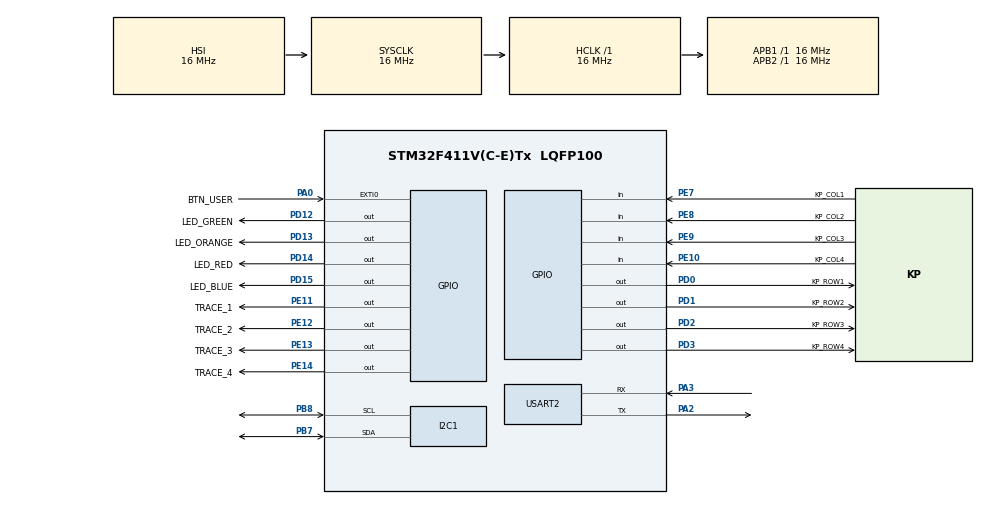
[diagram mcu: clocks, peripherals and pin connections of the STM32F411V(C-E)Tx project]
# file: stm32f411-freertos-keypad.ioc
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Dma.I2C1_TX.0.Direction=DMA_MEMORY_TO_PERIPH
Dma.I2C1_TX.0.FIFOMode=DMA_FIFOMODE_DISABLE
Dma.I2C1_TX.0.Instance=DMA1_Stream6
Dma.I2C1_TX.0.MemDataAlignment=DMA_MDATAALIGN_BYTE
Dma.I2C1_TX.0.MemInc=DMA_MINC_ENABLE
Dma.I2C1_TX.0.Mode=DMA_NORMAL
Dma.I2C1_TX.0.PeriphDataAlignment=DMA_PDATAALIGN_BYTE
Dma.I2C1_TX.0.PeriphInc=DMA_PINC_DISABLE
Dma.I2C1_TX.0.Priority=DMA_PRIORITY_LOW
Dma.Request0=I2C1_TX
FREERTOS.Tasks01=defaultTask,24,128,StartDefaultTask,Default,NULL,Dynamic,NULL,NULL
FREERTOS.configUSE_APPLICATION_TASK_TAG=1
Mcu.Family=STM32F4
Mcu.Name=STM32F411V(C-E)Tx
Mcu.Package=LQFP100
NVIC.DMA1_Stream6_IRQn=true\:5\:0\:false\:false\:true\:true\:false\:true\:true
NVIC.EXTI0_IRQn=true\:5\:0\:false\:false\:true\:true\:false\:true\:true
NVIC.I2C1_ER_IRQn=true\:5\:0\:false\:false\:true\:true\:true\:true\:true
NVIC.I2C1_EV_IRQn=true\:5\:0\:false\:false\:true\:true\:true\:true\:true
NVIC.PriorityGroup=NVIC_PRIORITYGROUP_4
NVIC.TIM1_TRG_COM_TIM11_IRQn=true\:15\:0\:false\:false\:true\:false\:false\:true\:true
NVIC.TimeBase=TIM1_TRG_COM_TIM11_IRQn
NVIC.TimeBaseIP=TIM11
PA0-WKUP.GPIO_Label=BTN_USER
PA0-WKUP.Signal=GPXTI0
PA13.Mode=Serial_Wire
PA13.Signal=SYS_JTMS-SWDIO
PA14.Mode=Serial_Wire
PA14.Signal=SYS_JTCK-SWCLK
PA2.Mode=Asynchronous
PA2.Signal=USART2_TX
PA3.Mode=Asynchronous
PA3.Signal=USART2_RX
PB7.GPIO_Pu=GPIO_PULLUP
PB7.Mode=I2C
PB7.Signal=I2C1_SDA
PB8.GPIO_Pu=GPIO_PULLUP
PB8.Mode=I2C
PB8.Signal=I2C1_SCL
PD0.GPIO_Label=KP_ROW1
PD0.GPIO_ModeDefaultOutputPP=GPIO_MODE_OUTPUT_OD
PD0.PinState=GPIO_PIN_SET
PD0.Signal=GPIO_Output
PD1.GPIO_Label=KP_ROW2
PD1.GPIO_ModeDefaultOutputPP=GPIO_MODE_OUTPUT_OD
PD1.PinState=GPIO_PIN_SET
PD1.Signal=GPIO_Output
PD12.GPIO_Label=LED_GREEN
PD12.Signal=GPIO_Output
PD13.GPIO_Label=LED_ORANGE
PD13.Signal=GPIO_Output
PD14.GPIO_Label=LED_RED
PD14.Signal=GPIO_Output
PD15.GPIO_Label=LED_BLUE
PD15.Signal=GPIO_Output
PD2.GPIO_Label=KP_ROW3
PD2.GPIO_ModeDefaultOutputPP=GPIO_MODE_OUTPUT_OD
PD2.PinState=GPIO_PIN_SET
PD2.Signal=GPIO_Output
PD3.GPIO_Label=KP_ROW4
PD3.GPIO_ModeDefaultOutputPP=GPIO_MODE_OUTPUT_OD
PD3.PinState=GPIO_PIN_SET
PD3.Signal=GPIO_Output
PE10.GPIO_Label=KP_COL4
PE10.GPIO_PuPd=GPIO_PULLUP
PE10.Signal=GPIO_Input
PE11.GPIO_Label=TRACE_1
PE11.GPIO_Speed=GPIO_SPEED_FREQ_HIGH
PE11.Signal=GPIO_Output
PE12.GPIO_Label=TRACE_2
PE12.GPIO_Speed=GPIO_SPEED_FREQ_HIGH
PE12.Signal=GPIO_Output
PE13.GPIO_Label=TRACE_3
PE13.GPIO_Speed=GPIO_SPEED_FREQ_HIGH
PE13.Signal=GPIO_Output
PE14.GPIO_Label=TRACE_4
PE14.GPIO_Speed=GPIO_SPEED_FREQ_HIGH
PE14.Signal=GPIO_Output
PE7.GPIO_Label=KP_COL1
PE7.GPIO_PuPd=GPIO_PULLUP
PE7.Signal=GPIO_Input
PE8.GPIO_Label=KP_COL2
PE8.GPIO_PuPd=GPIO_PULLUP
PE8.Signal=GPIO_Input
PE9.GPIO_Label=KP_COL3
PE9.GPIO_PuPd=GPIO_PULLUP
PE9.Signal=GPIO_Input
ProjectManager.HeapSize=0x200
ProjectManager.StackSize=0x400
ProjectManager.TargetToolchain=STM32CubeIDE
RCC.AHBFreq_Value=16000000
RCC.APB1Freq_Value=16000000
RCC.APB2Freq_Value=16000000
RCC.CortexFreq_Value=16000000
RCC.HSE_VALUE=25000000
RCC.HSI_VALUE=16000000
RCC.LSE_VALUE=32768
RCC.SYSCLKFreq_VALUE=16000000
RCC.VCOOutputFreq_Value=192000000
USART2.VirtualMode=VM_ASYNC
VP_FREERTOS_VS_CMSIS_V2.Mode=CMSIS_V2
VP_SYS_VS_tim11.Mode=TIM11
board=custom

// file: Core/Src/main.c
/* USER CODE BEGIN Header */
/**
  ******************************************************************************
  * @file           : main.c
  * @brief          : Main program body
  ******************************************************************************
  * Structure as generated by STM32CubeMX. Only edit between the
  * USER CODE BEGIN / USER CODE END markers - everything else is rewritten
  * when the code is regenerated from the .ioc file.
  ******************************************************************************
  */
/* USER CODE END Header */
#include "main.h"
#include "cmsis_os.h"

/* USER CODE BEGIN Includes */
#include "app.h"
/* USER CODE END Includes */

I2C_HandleTypeDef hi2c1;
DMA_HandleTypeDef hdma_i2c1_tx;

UART_HandleTypeDef huart2;

/* Definitions for defaultTask */
osThreadId_t defaultTaskHandle;
const osThreadAttr_t defaultTask_attributes = {
  .name = "defaultTask",
  .stack_size = 128 * 4,
  .priority = (osPriority_t) osPriorityNormal,
};

void SystemClock_Config(void);
static void MX_GPIO_Init(void);
static void MX_DMA_Init(void);
static void MX_I2C1_Init(void);
static void MX_USART2_UART_Init(void);
void StartDefaultTask(void *argument);

int main(void)
{

  /* MCU Configuration--------------------------------------------------------*/

  /* Reset of all peripherals, Initializes the Flash interface and the Systick. */
  HAL_Init();

  /* Configure the system clock */
  SystemClock_Config();

  /* Initialize all configured peripherals */
  MX_GPIO_Init();
  MX_DMA_Init();
  MX_I2C1_Init();
  MX_USART2_UART_Init();

  /* Init scheduler */
  osKernelInitialize();

  /* Create the thread(s) */
  /* creation of defaultTask */
  defaultTaskHandle = osThreadNew(StartDefaultTask, NULL, &defaultTask_attributes);

  /* USER CODE BEGIN RTOS_THREADS */
  /* add threads, ... */
  /* Creates all queues, semaphores and tasks of the application (see app.c) */
  App_Init();
  /* USER CODE END RTOS_THREADS */

  /* Start scheduler */
  osKernelStart();

  /* We should never get here as control is now taken by the scheduler */

  /* Infinite loop */
  while (1)
  {

  }
}

void SystemClock_Config(void)
{
  RCC_OscInitTypeDef RCC_OscInitStruct = {0};
  RCC_ClkInitTypeDef RCC_ClkInitStruct = {0};

  /** Configure the main internal regulator output voltage
  */
  __HAL_RCC_PWR_CLK_ENABLE();
  __HAL_PWR_VOLTAGESCALING_CONFIG(PWR_REGULATOR_VOLTAGE_SCALE1);

  /** Initializes the RCC Oscillators according to the specified parameters
  * in the RCC_OscInitTypeDef structure.
  */
  RCC_OscInitStruct.OscillatorType = RCC_OSCILLATORTYPE_HSI;
  RCC_OscInitStruct.HSIState = RCC_HSI_ON;
  RCC_OscInitStruct.HSICalibrationValue = RCC_HSICALIBRATION_DEFAULT;
  RCC_OscInitStruct.PLL.PLLState = RCC_PLL_NONE;
  if (HAL_RCC_OscConfig(&RCC_OscInitStruct) != HAL_OK)
  {
    Error_Handler();
  }

  /** Initializes the CPU, AHB and APB buses clocks
  */
  RCC_ClkInitStruct.ClockType = RCC_CLOCKTYPE_HCLK|RCC_CLOCKTYPE_SYSCLK
                              |RCC_CLOCKTYPE_PCLK1|RCC_CLOCKTYPE_PCLK2;
  RCC_ClkInitStruct.SYSCLKSource = RCC_SYSCLKSOURCE_HSI;
  RCC_ClkInitStruct.AHBCLKDivider = RCC_SYSCLK_DIV1;
  RCC_ClkInitStruct.APB1CLKDivider = RCC_HCLK_DIV1;
  RCC_ClkInitStruct.APB2CLKDivider = RCC_HCLK_DIV1;

  if (HAL_RCC_ClockConfig(&RCC_ClkInitStruct, FLASH_LATENCY_0) != HAL_OK)
  {
    Error_Handler();
  }
}

static void MX_I2C1_Init(void)
{

  hi2c1.Instance = I2C1;
  hi2c1.Init.ClockSpeed = 100000;
  hi2c1.Init.DutyCycle = I2C_DUTYCYCLE_2;
  hi2c1.Init.OwnAddress1 = 0;
  hi2c1.Init.AddressingMode = I2C_ADDRESSINGMODE_7BIT;
  hi2c1.Init.DualAddressMode = I2C_DUALADDRESS_DISABLE;
  hi2c1.Init.OwnAddress2 = 0;
  hi2c1.Init.GeneralCallMode = I2C_GENERALCALL_DISABLE;
  hi2c1.Init.NoStretchMode = I2C_NOSTRETCH_DISABLE;
  if (HAL_I2C_Init(&hi2c1) != HAL_OK)
  {
    Error_Handler();
  }

}

static void MX_USART2_UART_Init(void)
{

  huart2.Instance = USART2;
  huart2.Init.BaudRate = 115200;
  huart2.Init.WordLength = UART_WORDLENGTH_8B;
  huart2.Init.StopBits = UART_STOPBITS_1;
  huart2.Init.Parity = UART_PARITY_NONE;
  huart2.Init.Mode = UART_MODE_TX_RX;
  huart2.Init.HwFlowCtl = UART_HWCONTROL_NONE;
  huart2.Init.OverSampling = UART_OVERSAMPLING_16;
  if (HAL_UART_Init(&huart2) != HAL_OK)
  {
    Error_Handler();
  }

}

static void MX_DMA_Init(void)
{

  /* DMA controller clock enable */
  __HAL_RCC_DMA1_CLK_ENABLE();

  /* DMA interrupt init */
  /* DMA1_Stream6_IRQn interrupt configuration */
  HAL_NVIC_SetPriority(DMA1_Stream6_IRQn, 5, 0);
  HAL_NVIC_EnableIRQ(DMA1_Stream6_IRQn);

}

static void MX_GPIO_Init(void)
{
  GPIO_InitTypeDef GPIO_InitStruct = {0};

  /* GPIO Ports Clock Enable */
  __HAL_RCC_GPIOA_CLK_ENABLE();
  __HAL_RCC_GPIOE_CLK_ENABLE();
  __HAL_RCC_GPIOD_CLK_ENABLE();
  __HAL_RCC_GPIOB_CLK_ENABLE();

  /*Configure GPIO pin Output Level */
  HAL_GPIO_WritePin(GPIOE, TRACE_1_Pin|TRACE_2_Pin|TRACE_3_Pin|TRACE_4_Pin, GPIO_PIN_RESET);

  /*Configure GPIO pin Output Level */
  HAL_GPIO_WritePin(GPIOD, LED_GREEN_Pin|LED_ORANGE_Pin|LED_RED_Pin|LED_BLUE_Pin, GPIO_PIN_RESET);

  /*Configure GPIO pin Output Level */
  HAL_GPIO_WritePin(GPIOD, KP_ROW1_Pin|KP_ROW2_Pin|KP_ROW3_Pin|KP_ROW4_Pin, GPIO_PIN_SET);

  /*Configure GPIO pin : BTN_USER_Pin */
  GPIO_InitStruct.Pin = BTN_USER_Pin;
  GPIO_InitStruct.Mode = GPIO_MODE_IT_RISING;
  GPIO_InitStruct.Pull = GPIO_NOPULL;
  HAL_GPIO_Init(BTN_USER_GPIO_Port, &GPIO_InitStruct);

  /*Configure GPIO pins : KP_COL1_Pin KP_COL2_Pin KP_COL3_Pin KP_COL4_Pin */
  GPIO_InitStruct.Pin = KP_COL1_Pin|KP_COL2_Pin|KP_COL3_Pin|KP_COL4_Pin;
  GPIO_InitStruct.Mode = GPIO_MODE_INPUT;
  GPIO_InitStruct.Pull = GPIO_PULLUP;
  HAL_GPIO_Init(GPIOE, &GPIO_InitStruct);

  /*Configure GPIO pins : TRACE_1_Pin TRACE_2_Pin TRACE_3_Pin TRACE_4_Pin */
  GPIO_InitStruct.Pin = TRACE_1_Pin|TRACE_2_Pin|TRACE_3_Pin|TRACE_4_Pin;
  GPIO_InitStruct.Mode = GPIO_MODE_OUTPUT_PP;
  GPIO_InitStruct.Pull = GPIO_NOPULL;
  GPIO_InitStruct.Speed = GPIO_SPEED_FREQ_HIGH;
  HAL_GPIO_Init(GPIOE, &GPIO_InitStruct);

  /*Configure GPIO pins : LED_GREEN_Pin LED_ORANGE_Pin LED_RED_Pin LED_BLUE_Pin */
  GPIO_InitStruct.Pin = LED_GREEN_Pin|LED_ORANGE_Pin|LED_RED_Pin|LED_BLUE_Pin;
  GPIO_InitStruct.Mode = GPIO_MODE_OUTPUT_PP;
  GPIO_InitStruct.Pull = GPIO_NOPULL;
  GPIO_InitStruct.Speed = GPIO_SPEED_FREQ_LOW;
  HAL_GPIO_Init(GPIOD, &GPIO_InitStruct);

  /*Configure GPIO pins : KP_ROW1_Pin KP_ROW2_Pin KP_ROW3_Pin KP_ROW4_Pin */
  GPIO_InitStruct.Pin = KP_ROW1_Pin|KP_ROW2_Pin|KP_ROW3_Pin|KP_ROW4_Pin;
  GPIO_InitStruct.Mode = GPIO_MODE_OUTPUT_OD;
  GPIO_InitStruct.Pull = GPIO_NOPULL;
  GPIO_InitStruct.Speed = GPIO_SPEED_FREQ_LOW;
  HAL_GPIO_Init(GPIOD, &GPIO_InitStruct);

  /* EXTI interrupt init*/
  HAL_NVIC_SetPriority(EXTI0_IRQn, 5, 0);
  HAL_NVIC_EnableIRQ(EXTI0_IRQn);

}

void StartDefaultTask(void *argument)
{
  /* USER CODE BEGIN 5 */
  /* Not used by the application - all tasks are created in App_Init() */
  for(;;)
  {
    osDelay(1000);
  }
  /* USER CODE END 5 */
}

void HAL_TIM_PeriodElapsedCallback(TIM_HandleTypeDef *htim)
{
  if (htim->Instance == TIM11)
  {
    HAL_IncTick();
  }
}

void Error_Handler(void)
{
  __disable_irq();
  while (1)
  {
  }
}
